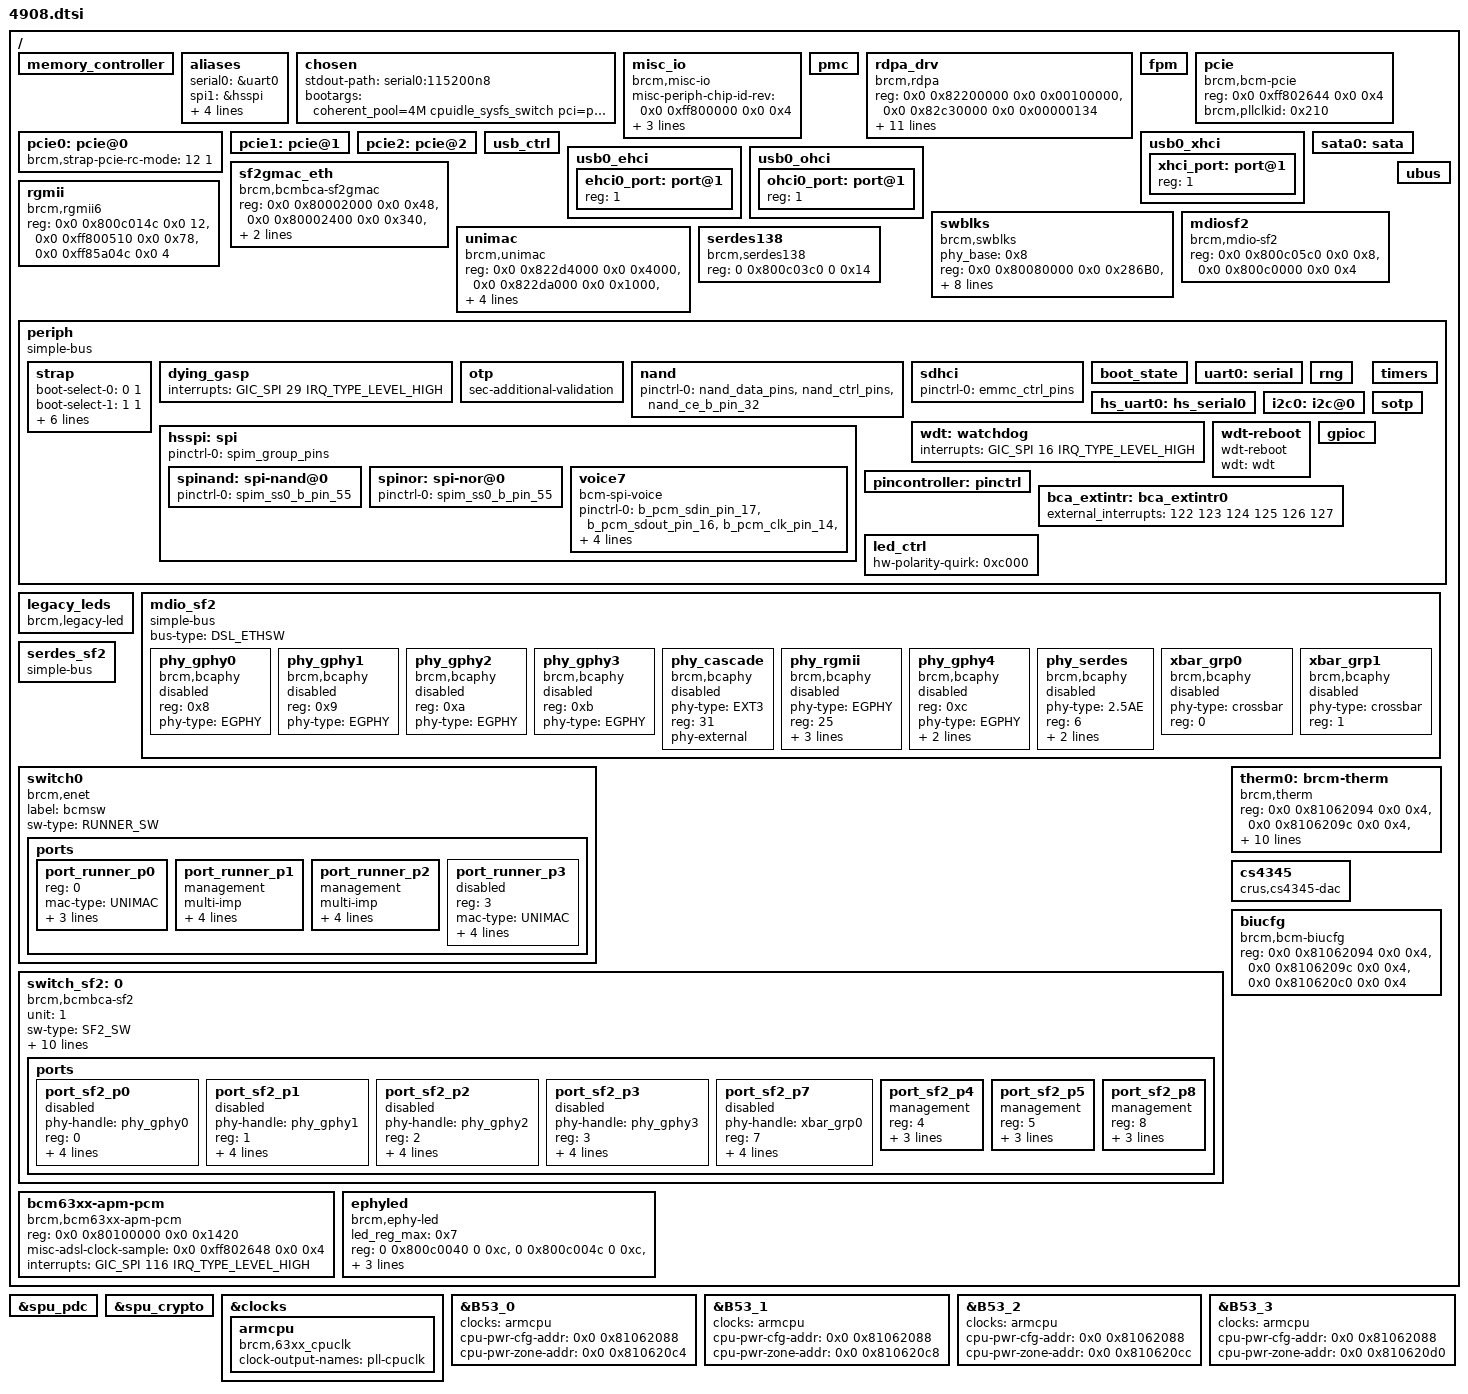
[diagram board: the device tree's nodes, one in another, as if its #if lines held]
/dts-v1/;

#include "linux_autoconf.h"

/* bootstrap reserved memory */
#include "../boot_rsvdmem.dtsi"

/ {
	/* arch */
	#define PMU_CORE0_SPI		9
	#define PMU_CORE1_SPI		10
	#define PMU_CORE2_SPI		11
	#define PMU_CORE3_SPI		12
	#include "../ip/bcm_b53_quad.dtsi"

	/* clocks */
	#define PERIPH_CLK		50000000
	#define HS_SPI_PLL_CLK	400000000
	#include "../ip/bcm_clocks.dtsi"

	/* broadcom memory reservations */
	#include "../bcm_rsvdmem.dtsi"

	/* memc */
	memory_controller {
		#define MEMC_REG_NAMES	"memc-int-clear-reg", \
					"memc-int-mask-clear-reg"

		#define MEMC_REG	<0 0x80018E08 0 4>, \
					<0 0x80018E14 0 4>

		#define MEMC_CPU_INT_LINE		18

		#include "../ip/memc.dtsi"
	};

	aliases {
		serial0 = &uart0;
		spi1 = &hsspi; /* 0 = legacy, 1 = high speed */
		spinand0 = &spinand;
		nand0 = &nand;
		spinor0 = &spinor;
		hs_serial0 = &hs_uart0;
	};

	chosen {
		stdout-path = "serial0:115200n8";
		/* increase coherent_pool size */
		bootargs = "coherent_pool=4M cpuidle_sysfs_switch pci=pcie_bus_safe console=ttyS0,115200 earlyprintk  rootwait rng_core.default_quality=1024";
	};

	misc_io {
		compatible = "brcm,misc-io";
		misc-periph-chip-id-rev = <0x0 0xff800000 0x0 0x4>;
		misc-periph-chip-id-mask = <0xfffff000>;
		misc-periph-chip-id-shift = <12>;
		misc-periph-chip-rev-mask = <0xfff>;
	};

	/* PMC */
	pmc: pmc {
		#define PMC_REG_OFFSET              0 0x80201000
		#define PMC_REG_SIZE                0 0x3800
		#define PROCMON_REG_OFFSET          0 0x80280000
		#define PROCMON_REG_SIZE            0 0x184
		#include "../ip/bcm_pmc_1_x.dtsi"
	};

	rdpa_drv {
		compatible = "brcm,rdpa";
		reg = <0x0 0x82200000 0x0 0x00100000>,
			<0x0 0x82c30000 0x0 0x00000134>;      /* FPM_BPM */
                interrupts = <GIC_SPI 56 IRQ_TYPE_LEVEL_HIGH>, /* INTERRUPT_FPM_INTR */
                             <GIC_SPI 45 IRQ_TYPE_LEVEL_HIGH>, /* INTERRUPT_RUNNER_INTR0 */
                             <GIC_SPI 46 IRQ_TYPE_LEVEL_HIGH>, /* INTERRUPT_RUNNER_INTR1 */
                             <GIC_SPI 47 IRQ_TYPE_LEVEL_HIGH>, /* INTERRUPT_RUNNER_INTR2 */
                             <GIC_SPI 48 IRQ_TYPE_LEVEL_HIGH>, /* INTERRUPT_RUNNER_INTR3 */
                             <GIC_SPI 49 IRQ_TYPE_LEVEL_HIGH>, /* INTERRUPT_RUNNER_INTR4 */
                             <GIC_SPI 50 IRQ_TYPE_LEVEL_HIGH>, /* INTERRUPT_RUNNER_INTR5 */
                             <GIC_SPI 51 IRQ_TYPE_LEVEL_HIGH>, /* INTERRUPT_RUNNER_INTR6 */
                             <GIC_SPI 52 IRQ_TYPE_LEVEL_HIGH>, /* INTERRUPT_RUNNER_INTR7 */
                             <GIC_SPI 53 IRQ_TYPE_LEVEL_HIGH>, /* INTERRUPT_RUNNER_INTR8 */
                             <GIC_SPI 54 IRQ_TYPE_LEVEL_HIGH>; /* INTERRUPT_RUNNER_INTR9 */
                interrupt-names = "fpm", "runner0", "runner1", "runner2", "runner3", "runner4",
                                  "runner5", "runner6", "runner7", "runner8", "runner9";
	};

	fpm {
		#define FPM_SPI_IRQ		88
		#define FPM_REG_ADDR		0 0x82c00000
		#define FPM_REG_SIZE		0 0x80000
		#define FPM_INIT		1
		#define FPM_TRACK_TOKENS	1
		#define FPM_TRACK_ON_ERROR	0
		#define FPM_POOL_O_ALLOC_WEIGHT	1
		#define FPM_POOL_1_ALLOC_WEIGHT	1
		#define FPM_POOL_O_FREE_WEIGHT	1
		#define FPM_POOL_1_FREE_WEIGHT	1
		#include "../ip/bcm_fpm.dtsi"
	};

#if defined(CONFIG_BCM_PCIE_HCD) || defined(CONFIG_BCM_PCIE_HCD_MODULE)
	/* pcie common */
	pcie: pcie {
		compatible = "brcm,bcm-pcie";
		device_type = "cpci";
		reg = <0x0 0xff802644 0x0 0x4>; /* PERIPH_MISC_PCIECtrl */
		brcm,pllclkid = <0x210>;
	};

	/* pcie core 0 */
	pcie0: pcie@0 {
		#define PCIE_ID				0
		#define PCIE_SPI			59
		#define PCIE_ADDR			0x80040000
		#define PCIE_SIZE			0x0000A000
		#define PCIE_RANGE_ADDR		0xC0000000
		#define PCIE_RANGE_SIZE		0x10000000
		#include "../ip/bcm_pcie_core.dtsi" 
		brcm,strap-pcie-rc-mode=<12 1>; 
	};

	/* pcie core 1 */
	pcie1: pcie@1 {
		#define PCIE_ID				1
		#define PCIE_SPI			60
		#define PCIE_ADDR			0x80050000
		#define PCIE_SIZE			0x0000A000
		#define PCIE_RANGE_ADDR		0xD0000000
		#define PCIE_RANGE_SIZE		0x10000000
		#include "../ip/bcm_pcie_core.dtsi"
	};

	/* pcie core 2 */
	pcie2: pcie@2 {
		#define PCIE_ID				2
		#define PCIE_SPI			61
		#define PCIE_ADDR			0x80060000
		#define PCIE_SIZE			0x0000A000
		#define PCIE_RANGE_ADDR		0xE0000000
		#define PCIE_RANGE_SIZE		0x10000000
		#include "../ip/bcm_pcie_core.dtsi"
	};
#endif /* defined(CONFIG_BCM_PCIE_HCD) || defined(CONFIG_BCM_PCIE_HCD_MODULE) */

#if (defined(CONFIG_BCM_PDC) || defined(CONFIG_BCM_PDC_MODULE)) && \
    (defined(CONFIG_BCM_SPU) || defined(CONFIG_BCM_SPU_MODULE))
	/* spu */
	#define SPU_DMA_ADDR			0x00000000 0x8001c000
	#define SPU_DMA_SIZE			0x00000000 0x448
	#define SPU_DMA_NUM_CHAN		1
	#define SPU_DMA_NUM_AE			1
	#define SPU_CRYPTO_ADDR			0x00000000 0x8001d000
	#define SPU_CRYPTO_SIZE			0x00000000 0x64
	#define SPU_GMAC_SPI			90
	#include "../ip/bcm_spu.dtsi"
#endif

	/* usb */
	usb_ctrl: usb_ctrl {
		#define USB_CTRL_ADDR	0x0 0x8000c200
		#define USB_CTRL_SIZE	0x0 0x100
		#include "../ip/bcm_usb_ctrl.dtsi"
	};

	usb0_xhci: usb0_xhci {
		#define USB_ADDR    0x0 0x8000d000
		#define USB_SIZE    0x0 0x1000
		#define USB_IRQ     74 
		#include "../ip/bcm_usb_xhci.dtsi"

		xhci_port: port@1{
			reg = <1>;
			#trigger-source-cells = <0>;
		};
	};

	usb0_ehci: usb0_ehci {
		#define USB_ADDR	0x0 0x8000c300
		#define USB_SIZE	0x0 0x100
		#define USB_IRQ		73
		#include "../ip/bcm_usb_ehci.dtsi"

 		ehci0_port: port@1{
			reg = <1>;
			#trigger-source-cells = <0>;
		};
	};

	usb0_ohci: usb0_ohci {
		#define USB_ADDR	0x0 0x8000c400
		#define USB_SIZE	0x0 0x100
		#define USB_IRQ		72
		#include "../ip/bcm_usb_ohci.dtsi"

 		ohci0_port: port@1{
			reg = <1>;
			#trigger-source-cells = <0>;
		};
	};

	sata0: sata {
		#define AHCI_ADDR		0x0 0x8000a000
		#define AHCI_SIZE		0x0 0x2c
		#define SATA_CTRL_ADDR	0x0 0x80008000
		#define SATA_CTRL_SIZE	0x0 0x2000
		#define AHCI_SS_ADDR	0x0 0x8000a100
		#define AHCI_SS_SIZE	0x0 0x80
		#define AHCI_IRQ		44
		#include "../ip/bcm_sata.dtsi"
	};

	sf2gmac_eth {
		compatible = "brcm,bcmbca-sf2gmac";
		reg-names = "gmac-intf-base",
				"gmac-mac-base",
				"gmac-dma-base";

		reg = <0x0 0x80002000 0x0 0x48>,
			<0x0 0x80002400 0x0 0x340>,
			<0x0 0x80002800 0x0 0x420>;

		ethsw = <&switch_sf2>;
	};

	swblks {
		compatible = "brcm,swblks";
		phy_base = <0x8>;
		reg-names = "switchcore-base",
				"switchreg-base",
				"switchmdio-base",
				"switchfcb-base",
				"switchacb-base",
				"xbar-ctrl",
				"qphy-ctrl",
				"sphy-ctrl",
				"phy-test-ctrl";

		reg = <0x0 0x80080000 0x0 0x286B0>,
			<0x0 0x800C0000 0x0 0x3F4>,
			<0x0 0x800C05C0 0x0 0x8>,
			<0x0 0x800C0600 0x0 0x34>,
			<0x0 0x800C0800 0x0 0x208>,
			<0x0 0x800C00C8 0x0 0x04>,
			<0x0 0x800C001C 0x0 0x04>,
			<0x0 0x800C0024 0x0 0x04>,
			<0x0 0x800C0018 0x0 0x04>;
	};

	mdiosf2 {
		compatible = "brcm,mdio-sf2";
		reg = <0x0 0x800c05c0 0x0 0x8>,
		      <0x0 0x800c0000 0x0 0x4>;
	};

	rgmii: rgmii {
		compatible = "brcm,rgmii6";     /* rgmii0 P11 crossbar external EP1 */
		reg = <0x0 0x800c014c 0x0 12>,  /* SWITCH_REG->RGMII_11_CNTRL */
		      <0x0 0xff800510 0x0 0x78>,/* GPIO */
		      <0x0 0xff85a04c 0x0 4>;   /* TOP_CONTROL->RGMII_CONTROL */
	};

	unimac {
		compatible = "brcm,unimac";
		reg = <0x0 0x822d4000 0x0 0x4000>,
			  <0x0 0x822da000 0x0 0x1000>,
			  <0x0 0x822db800 0x0 0x1000>;
		conf_offset = <0x1000>;
		mib_offset = <0x400>;
		top_offset = <0x400>;
	};

	serdes138 {
		compatible = "brcm,serdes138";
		reg = <0 0x800c03c0 0 0x14>;   /* SINGLE_SERDES */
	};

	ubus: ubus {
		#define UBUS_SYSTOP_OFFSET		0x0 0x810621D8
		#define UBUS_SYSTOP_SIZE		0x0 0x24
		#include "../ip/bcm_ubus3.dtsi"
	};

	periph {
		compatible = "simple-bus";
		#address-cells = <2>;
		#size-cells = <2>;
		ranges = <0x0 0x0 0x0 0xff800000 0x0 0x62000>;

		strap: strap {
			#define STRAP_REG_OFFSET		0x0 0x2600
			#define STRAP_REG_SIZE			0x0 0x4
			#include "../ip/bcm_strap.dtsi"
			boot-select-0=<0 1>;
			boot-select-1=<1 1>;
			boot-select-2=<2 1>;
			boot-select-3=<3 1>;
			boot-select-4=<4 1>;
			boot-select-5=<5 1>;
			bootrom-boot=<7 0>;
			strap-cpu-slow-freq=<16 1>;
		};

		dying_gasp: dying_gasp {
			#define DG_PERIPH_REG_OFFSET	0x0 0x5A034
			#define DG_PERIPH_REG_SIZE		0x0 0x4
			#define DG_UART_DR_OFFSET		0x0 0x654
			#define DG_UART_DR_SIZE			0x0 0x4
			#include "../ip/bcm_dgasp_periph.dtsi"
			interrupts = <GIC_SPI 29 IRQ_TYPE_LEVEL_HIGH>;
		};

		otp: otp {
			#define OTP_REG_OFFSET			0x0 0xe00
			#define OTP_REG_SIZE			0x0 0x3c
			#include "../ip/bcm_otp.dtsi"
			sec-additional-validation;
		};

		/* NAND controller */
		nand: nand {
			pinctrl-0 = <&nand_data_pins &nand_ctrl_pins &nand_ce_b_pin_32>;
			pinctrl-names = "default";
			#define NAND_CTRL_OFFSET		0x0 0x1800
			#define NAND_CTRL_SIZE			0x0 0x400
			#define NAND_INTR_OFFSET		0x0 0x2000
			#define NAND_INTR_SIZE			0x0 0x10
			#define NAND_CACHE_OFFSET		0x0 0x1C00
			#define NAND_CACHE_SIZE			0x0 0x200
			#include "../ip/bcm_nand7_1.dtsi"
		};

		/* EMMC */
		sdhci: sdhci {
			pinctrl-0 = <&emmc_ctrl_pins>;
			pinctrl-names="default";
			#define SDHCI_OFFSET			0x00000000 0x58000
			#define SDHCI_SIZE				0x00000000 0x100
			#define SDHCI_TOPCFG_OFFSET		0x00000000 0x58100
			#define SDHCI_TOPCFG_SIZE		0x00000000 0x100
			#define SDHCI_BOOT_OFFSET		0x00000000 0x58200
			#define SDHCI_BOOT_SIZE			0x00000000 0x40
			#define SDHCI_AHBSS_CTRL_OFFSET	0x00000000 0x58300
			#define SDHCI_AHBSS_CTRL_SIZE	0x00000000 0x100
			#define SDIO_EMMC_SPI			85
			#define EMMC_DDR_1_8V
			#include "../ip/bcm_sdhci.dtsi"
		};

		/* boot state */
		boot_state: boot_state {
			#define RESET_STATUS_OFFSET		0x0 0x438
			#define RESET_STATUS_SIZE		0x0 0x04
			#define RESET_REASON_OFFSET	0x0 0x2628
			#define RESET_REASON_SIZE		0x0 0x4
			#include "../ip/bcm_boot_state_v2.dtsi"
		};

		/* UART 1*/
		uart0: serial {
			#define UART_OFFSET			0x0 0x640
			#define UART_SIZE			0x0 0x20
			#define UART_SPI			32
			#include "../ip/bcm_uart.dtsi"
		};

		hs_uart0: hs_serial0 {
			#define UART_OFFSET			0x0 0x58400
			#define UART_SIZE			0x0 0x1E0
			#define UART_SPI 			34
			#include "../ip/bcm_hs_uart.dtsi"
		};

		/* HS SPI */
		hsspi: spi {
			pinctrl-0 = <&spim_group_pins>;
			pinctrl-names = "default";
			#define HS_SPI_OFFSET			0x0 0x1000
			#define HS_SPI_SIZE			0x0 0x600
			#define HS_SPI_MAX_FREQ			50000000
			/* #define HS_SPIM_SPI			36 */
			#include "../ip/bcm_hsspi.dtsi"
			spinand: spi-nand@0 {
				pinctrl-0 = <&spim_ss0_b_pin_55>;
				pinctrl-names = "default";
				#define SPINAND_MAX_FREQ	50000000
				#include "../ip/bcm_spinand.dtsi"
			};

			spinor: spi-nor@0 {
				pinctrl-0 = <&spim_ss0_b_pin_55>;
				pinctrl-names = "default";			
				#define SPINOR_MAX_FREQ	50000000
				#include "../ip/bcm_spinor.dtsi"
			};

			voice7 {
				pinctrl-0 = <&b_pcm_sdin_pin_17 &b_pcm_sdout_pin_16 &b_pcm_clk_pin_14 &b_pcm_frame_sync_pin_15>;
				pinctrl-names = "default";
				compatible = "bcm-spi-voice";
				reg = <7>; /* chip select 7 */
				spi-index = <7>;/* ZSI/ISI header position index */
				spi-max-frequency = <1024000>;
			};
		};

		rng: rng {
			#define RNG200_OFFSET			0x0 0x00000b80
			#define RNG200_SIZE			0x0 0x28
			#include "../ip/bcm_rng200.dtsi"
		};

		i2c0: i2c@0 {
			#define I2C_OFFSET			0x0 0x2100
			#define I2C_SIZE			0x0 0x60
			#include "../ip/bcm_i2c_bus.dtsi"
		};

		/* periph timers */
		timers: timers {
			#define TIMERS_OFFSET		0x0 0x400
			#define TIMERS__SIZE		0x0 0x28
			#define TIMER0_SPI			64
			#define TIMER1_SPI			65
			#define TIMER2_SPI			66
			#define TIMER3_SPI			67
			#include "../ip/bcm_timer.dtsi"
		};

		/* watchdog */
		wdt: watchdog {
			#define WATCHDOG_OFFSET			0x0 0x428
			#define WATCHDOG_SIZE			0x0 0x10
			#define WATCHDOG_TIMEOUT		80
			#include "../ip/bcm_wdt.dtsi"
			interrupts = <GIC_SPI 16 IRQ_TYPE_LEVEL_HIGH>;
		};

		/* watchdog reboot */
		wdt-reboot {
			compatible = "wdt-reboot";
			wdt = <&wdt>;
		};

		/* sotp */
		sotp {
			#define SOTP_OFFSET			0x0 0xc00
			#define SOTP_SIZE			0x0 0x84
			#include "../ip/bcm_sotp.dtsi"
		};
		
		/* pinctrl */
		pincontroller: pinctrl {
			#define PINCTRL_OFFSET       0x0 0x564
			#define PINCTRL_SIZE         0x0 0xc
			#define PINCTRL_NUM_PINS     86
			#define PINCTRL_NUM_FUNC     8
			#define PINCTRL_GPIO_FUNC    4
			#include "../ip/bcm_bca_pinctrl.dtsi"
			#include "4908_pinctrl.dtsi"
		};

		/* gpio */
		gpioc: gpioc {
			#define GPIO_DIR_OFFSET      0x0 0x500
			#define GPIO_DIR_SIZE        0x0 0x28
			#define GPIO_DATA_OFFSET     0x0 0x528
			#define GPIO_DATA_SIZE       0x0 0x28
			#define NUM_OF_GPIOS         86
			#include "../ip/bcm_bca_gpio.dtsi"
		};

		/* external interrups */
		bca_extintr: bca_extintr0 {
			#define EXTINTR_OFFSET       0x0 0xc
			#define EXTINTR_SIZE         0x0 0x18
			#define MAX_EXT_INTR         6
			#include "../ip/bcm_bca_extintr.dtsi"
			external_interrupts = <122 123 124 125 126 127>;
		};
		/* Led Controller */
		led_ctrl: led_ctrl {
			#define LED_GLBL_CTRL_OFFSET     0 0x800
			#define LED_GLBL_CTRL_SIZE       0 0x4 
			#define LED_HW_EN_OFFSET         0 0x808
			#define LED_HW_EN_SIZE           0 0x4
			#define LED_SER_SHIFT_OFFSET     0 0x80c
			#define LED_SER_SHIFT_SIZE       0 0x4
			#define LED_FLASH_RATE_OFFSET    0 0x810
			#define LED_FLASH_RATE_SIZE      0 0x10
			#define LED_BRIGHTNESS_OFFSET    0 0x820
			#define LED_BRIGHTNESS_SIZE      0 0x10
			#define LED_POWER_LED_CFG_OFFSET 0 0x830
			#define LED_POWER_LED_CFG_SIZE   0 0x4
			#define LED_POWER_LUT_OFFSET     0 0x834
			#define LED_POWER_LUT_SIZE       0 0x80
			#define LED_HW_POLARITY_OFFSET   0 0x8b4
			#define LED_HW_POLARITY_SIZE     0 0x4
			#define LED_SW_DATA_OFFSET       0 0x8b8
			#define LED_SW_DATA_SIZE         0 0x4
			#define LED_SW_POLARITY_OFFSET   0 0x8bc
			#define LED_SW_POLARITY_SIZE     0 0x4
			#define LED_PAR_POLARITY_OFFSET  0 0x8c0
			#define LED_PAR_POLARITY_SIZE    0 0x4
			#define LED_SER_POLARITY_OFFSET  0 0x8c4
			#define LED_SER_POLARITY_SIZE    0 0x4
			#define LED_MASK_OFFSET          0 0x804 /*????*/
			#define LED_MASK_SIZE            0 0x4
			#define MAX_SUPPORTED_LEDS       32

			status = "okay";
			hw-polarity-quirk = <0xc000>;
			#include "../ip/bcm_led_ctrl.dtsi"
			#include "4908_leds.dtsi"
		};		
	};

	legacy_leds: legacy_leds {
		compatible = "brcm,legacy-led";
	};

	mdio_sf2: mdio_sf2 {
		compatible = "simple-bus";
		bus-type = "DSL_ETHSW";
		#address-cells = <1>;
		#size-cells = <0>;

		/* Port PHY mapping:
           port_runner_p0  <-->  port_sf2_p8 -###- port_sf2_p0 <------------------> phy_gphy0
           port_runner_p1  <-->  port_sf2_p5 -# #- port_sf2_p1 <------------------> phy_gphy1
           port_runner_p2  <-->  port_sf2_p4 -# #- port_sf2_p2 <------------------> phy_gphy2
                                              # #- port_sf2_p3 <------------------> phy_gphy3
                                              ###- port_sf2_p7 <--> xbar_grp0 -+-+- phy_serdes
                                                   port_runner_p3 <--> xbar_grp1 -+ +- phy_gphy4
                                                                                    +-+- phy_rgmii         
		*/
		/* PHYs directly connected to SF2 */
		phy_gphy0:phy_gphy0 {
			compatible = "brcm,bcaphy";
			reg = <0x8>;
			phy-type = "EGPHY";
			status = "disabled";
		};
		phy_gphy1:phy_gphy1 {
			compatible = "brcm,bcaphy";
			reg = <0x9>;
			phy-type = "EGPHY";
			status = "disabled";
		};
		phy_gphy2:phy_gphy2 {
			compatible = "brcm,bcaphy";
			reg = <0xa>;
			phy-type = "EGPHY";
			status = "disabled";
		};
		phy_gphy3:phy_gphy3 {
			compatible = "brcm,bcaphy";
			reg = <0xb>;
			phy-type = "EGPHY";
			status = "disabled";
		};

		/* Cascade PHYs */
		phy_cascade:phy_cascade {
			compatible = "brcm,bcaphy";
			phy-type = "EXT3";
			reg = <31>;
			status = "disabled";
			phy-external;
		};

		/* PHYs connected to crossbar */
		phy_rgmii:phy_rgmii {
			compatible = "brcm,bcaphy";
			phy-type = "EGPHY";
			reg = <25>;
			xbar-ext-ep = <2>;          /* external endpoint2 */
			phy-mode = "rgmii";
			phy-external;
			status = "disabled";
		};
		phy_gphy4:phy_gphy4 {
			compatible = "brcm,bcaphy";
			reg = <0xc>;
			phy-type = "EGPHY";
			xbar-ext-ep = <1>;          /* external endpoint1 */
			phy-mode = "gmii";
			status = "disabled";
		};
		phy_serdes:phy_serdes {
			compatible = "brcm,bcaphy";
			phy-type = "2.5AE";
			reg = <6>;
			xbar-ext-ep = <0>;          /* external endpoint0 */
			phy-mode = "serdes";
			status = "disabled";
		};

		/* Crossbar groups */
		xbar_grp0:xbar_grp0 {                   /* internal endpoint0 SF2.p7 */
			compatible = "brcm,bcaphy";
			phy-type = "crossbar";
			reg = <0>;
			status = "disabled";
		};
		xbar_grp1:xbar_grp1 {                   /* internal endpoint1 runner.p3 */
			compatible = "brcm,bcaphy";
			phy-type = "crossbar";
			reg = <1>;
			status = "disabled";
		};
	};

	serdes_sf2: serdes_sf2 {
		compatible = "simple-bus";
	};

	switch0:switch0 {
		compatible = "brcm,enet";
		label = "bcmsw";
		sw-type = "RUNNER_SW";

		ports {
			#address-cells = <1>;
			#size-cells = <0>;

			port_runner_p0 {
				reg = <0>;
				mac-type = "UNIMAC";
				link = <&switch_sf2>;   /* runner.p0 <--> sf2.p8 */
				phy-mode = "gmii";
				gmii-direct;
				status = "okay";
			};
			port_runner_p1 {
				management; multi-imp;  /* runner.p1 <--> sf2.p5 */
				reg = <1>;
				mac-type = "UNIMAC";
				phy-mode = "gmii";
				gmii-direct;
				status = "okay";
			};
			port_runner_p2 {
				management; multi-imp;  /* runner.p2 <--> sf2.p4 */
				reg = <2>;
				mac-type = "UNIMAC";
				phy-mode = "gmii";
				gmii-direct;
				status = "okay";
			};
				
			port_runner_p3 {
				reg = <3>;
				mac-type = "UNIMAC";
				phy-handle = <&xbar_grp1>;
				gmii-direct;
				phy-mode = "serdes";
				cap-wan-only;
				status = "disabled";
			};
		};
	};

	switch_sf2:0 {
		unit= <1>;
		sw-type = "SF2_SW";

		compatible = "brcm,bcmbca-sf2";
		phy_base = <0x8>;
		reg-names = "switchcore-base",
				"switchreg-base",
				"switchmdio-base",
				"switchfcb-base",
				"switchacb-base",
				"xbar-ctrl",
				"qphy-ctrl",
				"sphy-ctrl",
				"phy-test-ctrl";

		reg = <0x0 0x80080000 0x0 0x286B0>,
			<0x0 0x800C0000 0x0 0x3F4>,
			<0x0 0x800C05C0 0x0 0x8>,
			<0x0 0x800C0600 0x0 0x34>,
			<0x0 0x800C0800 0x0 0x208>,
			<0x0 0x800C00C8 0x0 0x04>,
			<0x0 0x800C001C 0x0 0x04>,
			<0x0 0x800C0024 0x0 0x04>,
			<0x0 0x800C0018 0x0 0x04>;

		ports {
			#address-cells = <1>;
			#size-cells = <0>;
			
			/* ports connect directly */
			port_sf2_p0 {
				phy-handle = <&phy_gphy0>;
				reg = <0>;
				mac-type = "SF2MAC";
				phy-mode = "gmii";
				gmii-direct;
				cap-lan-only;
				status = "disabled";
			};
			port_sf2_p1 {
				phy-handle = <&phy_gphy1>;
				reg = <1>;
				mac-type = "SF2MAC";
				phy-mode = "gmii";
				gmii-direct;
				cap-lan-only;
				status = "disabled";
			};
			port_sf2_p2 {
				phy-handle = <&phy_gphy2>;
				reg = <2>;
				mac-type = "SF2MAC";
				phy-mode = "gmii";
				gmii-direct;
				cap-lan-only;
				status = "disabled";
			};
			port_sf2_p3 {
				phy-handle = <&phy_gphy3>;
				reg = <3>;
				mac-type = "SF2MAC";
				phy-mode = "gmii";
				gmii-direct;
				cap-lan-only;
				status = "disabled";
			};

			/* ports connected to crossbar */
			port_sf2_p7 {
				phy-handle = <&xbar_grp0>;
				reg = <7>;
				mac-type = "SF2MAC";
				phy-mode = "gmii";
				gmii-direct;
				cap-lan-only;
				status = "disabled";
			};

			/* IMP ports */
			port_sf2_p4 {
				management;     /* sf2.p4 <--> runner.p2 */
				reg = <4>;
				mac-type = "SF2MAC";
				phy-mode = "gmii";
				gmii-direct;
				status = "okay";
			};
			port_sf2_p5 {
				management;     /* sf2.p5 <--> runner.p1 */
				reg = <5>;
				mac-type = "SF2MAC";
				phy-mode = "gmii";
				gmii-direct;
				status = "okay";
			};
			port_sf2_p8 {
				management;     /* sf2.p8 <--> runner.p0 */
				reg = <8>;
				mac-type = "SF2MAC";
				phy-mode = "gmii";
				gmii-direct;
				status = "okay";
			};
		};
	};

	bcm63xx-apm-pcm {
		compatible = "brcm,bcm63xx-apm-pcm";
		reg = <0x0 0x80100000 0x0 0x1420>;
		misc-adsl-clock-sample = <0x0 0xff802648 0x0 0x4>;
		interrupts = <GIC_SPI 116 IRQ_TYPE_LEVEL_HIGH>;
	};		

	ephyled {
		compatible = "brcm,ephy-led";
		led_reg_max = <0x7>;
		/* only define the switch led reg that are actually used.*/
		/* sf2 port0, sf2 port1, sf2 port 2, sf2 port3, sf2 port7, sf2 wan port */		
		reg-names = "led_reg_0", "led_reg_1", "led_reg_2", "led_reg_3", "led_reg_4",\
			"led_reg_5", "aggregate_ctrl";
		reg = <0 0x800c0040 0 0xc>, <0 0x800c004c 0 0xc>, <0 0x800c0058 0 0xc>,\
			<0 0x800c0064 0 0xc>, <0 0x800c0088 0 0xc>, <0 0x800c00a0 0 0xc>, <0 0x800c00b8 0 0x4>;
	};

	therm0: brcm-therm {
		compatible = "brcm,therm";
		reg-names = 
#ifndef CONFIG_BCM_CPUIDLE_CLK_DIVIDER
			"cluster_clk_ctrl0",
			"cluster_clk_pattern0",
#endif
			"bac_cpu_therm_temp";	/* biuctl_therm_throttle_temp */
		reg =
#ifndef CONFIG_BCM_CPUIDLE_CLK_DIVIDER
			<0x0 0x81062094 0x0 0x4>,
			<0x0 0x8106209c 0x0 0x4>,
#endif
			<0x0 0x810621a0 0x0 0x4>;

            /* Cold compensation */
            threshold0 = <25>; /* celsius */
            hysteresis0 = <10>; /* celsius */
            enabled0;

            /* CPU cores step 1 */
            threshold1 = <115>; /* celsius */
            hysteresis1 = <2>; /* celsius */

            /* CPU cores step 2 */
            threshold2 = <125>; /* celsius */
            hysteresis2 = <2>; /* celsius */

            /* CPU Freq */
            threshold3 = <110>; /* celsius */
            hysteresis3 = <2>; /* celsius */
	};

	cs4345 {
		compatible = "crus,cs4345-dac";
	};

#if defined(CONFIG_BCM_CPUIDLE_CLK_DIVIDER)
	biucfg {
		compatible = "brcm,bcm-biucfg";
		reg-names = "cluster_clk_ctrl0",
				"cluster_clk_pattern0",
				"wfx_state";
		reg = <0x0 0x81062094 0x0 0x4>,
				<0x0 0x8106209c 0x0 0x4>,
				<0x0 0x810620c0 0x0 0x4>;
	};
#endif
};

&nand {
	status = "okay";
};
&uart0 {
	status = "okay";
};
&wdt {
	status = "okay";
};
&i2c0 {
	status = "okay";
};
&sdhci {
	status = "okay";
};
&hsspi {
	status = "okay";
};
&spinand {
	status = "okay";
};
&spinor {
	status = "okay";
};

#if (defined(CONFIG_BCM_PDC) || defined(CONFIG_BCM_PDC_MODULE)) && \
    (defined(CONFIG_BCM_SPU) || defined(CONFIG_BCM_SPU_MODULE))
&spu_pdc {
	status = "okay";
};
&spu_crypto {
	status = "okay";
};
#endif

&clocks {
	armcpu: armcpu {
		#clock-cells = <0>;
		compatible = "brcm,63xx_cpuclk";
		clock-output-names = "pll-cpuclk";
	};
};

&B53_0 {
		clocks = <&armcpu>;
		clock-names = "cpuclk";
		cpu-pwr-cfg-addr = <0x0 0x81062088>;
		cpu-pwr-zone-addr = <0x0 0x810620c4>;
};

&B53_1 {
		clocks = <&armcpu>;
		clock-names = "cpuclk";
		cpu-pwr-cfg-addr = <0x0 0x81062088>;
		cpu-pwr-zone-addr = <0x0 0x810620c8>;
};

&B53_2 {
		clocks = <&armcpu>;
		clock-names = "cpuclk";
		cpu-pwr-cfg-addr = <0x0 0x81062088>;
		cpu-pwr-zone-addr = <0x0 0x810620cc>;
};

&B53_3 {
		clocks = <&armcpu>;
		clock-names = "cpuclk";
		cpu-pwr-cfg-addr = <0x0 0x81062088>;
		cpu-pwr-zone-addr = <0x0 0x810620d0>;
};
